# ESP32S31_RADIO register map
Vendor: Espressif; Series: ESP32-S31; File version: 3.52
Registers are 32-bit, read-write, no defined reset value unless marked. A register's access mark holds for its fields unless they carry their own. Offsets are from the block's base; [hi:lo] are bit positions.

## WIFI_MAC_INTERNAL_TX_BLOCK_ACK — Complete dbg_read_internal_txba reads one internal WDEVTXBA result: a 64-bit bitmap, two transmitter-address words and a combined fragment/starting-sequence/TID word.
Base 0x2010429C
0x00 BITMAP_HIGH ro
  [31:0] BITMAP — High 32 bits of the internal transmit BlockAck acknowledgement bitmap.
0x04 BITMAP_LOW ro
  [31:0] BITMAP — Low 32 bits of the internal transmit BlockAck acknowledgement bitmap.
0x08 TRANSMITTER_ADDRESS_WORD_0 ro — First WDEVTXBA TA word printed by the complete blob decoder. Byte ordering is retained as a raw word until a matching live frame qualifies it.
0x0C TRANSMITTER_ADDRESS_WORD_1 ro — Second WDEVTXBA TA word printed by the complete blob decoder. Byte ordering is retained as a raw word until a matching live frame qualifies it.
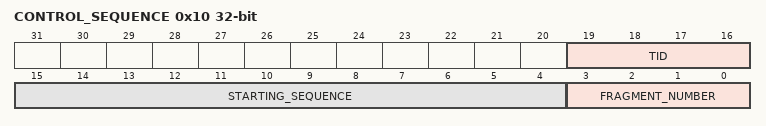
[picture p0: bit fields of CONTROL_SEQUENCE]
0x10 CONTROL_SEQUENCE ro
  [19:16] TID, [15:4] STARTING_SEQUENCE, [3:0] FRAGMENT_NUMBER

## WIFI_MAC_HE_COLOR_COLLISION — Complete dbg_read_color_collision reads the 64-bit observed BSS-color bitmap. Its adjacent control word is the canonical WIFI_MAC_HE_INIT_PREFIX.RX_FIELD_CONTROL register. Open HE HIL observed color bit 25, threshold one and timeout 60 seconds.
Base 0x20104040
0x00 BSS_COLOR_BITMAP_LOW ro — RX_HE_BSS_COLOR_MAPLO.
  [31:0] VALUE
0x04 BSS_COLOR_BITMAP_HIGH ro — RX_HE_BSS_COLOR_MAPHI.
  [31:0] VALUE

## WIFI_MAC_RX_POWER_SAVE — WDEV_RX_POWER_SAVE_CONF decoded by complete dbg_read_rx_misc. Complete hal_he_set_power_save sets the interface-zero intra-PPDU and BSS-color-check bits as the tail of hal_he_bssid_init; open associated-STA HIL read both bits set.
Base 0x201040A0
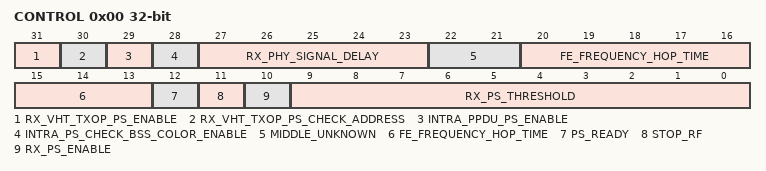
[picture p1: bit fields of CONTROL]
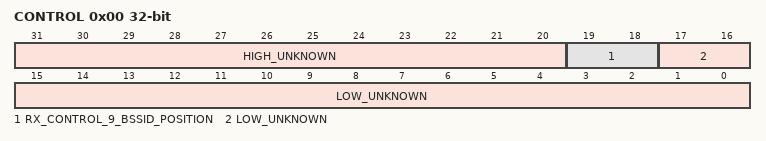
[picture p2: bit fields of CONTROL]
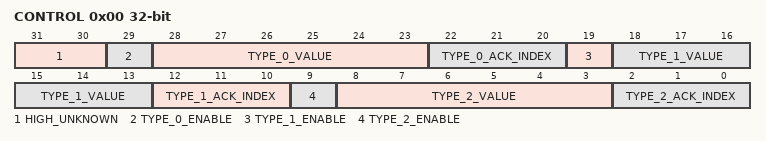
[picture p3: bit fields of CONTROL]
0x00 CONTROL
  [31] RX_VHT_TXOP_PS_ENABLE
  [30] RX_VHT_TXOP_PS_CHECK_ADDRESS
  [29] INTRA_PPDU_PS_ENABLE — Complete hal_he_set_power_save sets bit 29 for interface zero immediately before bit 28; dbg_read_rx_misc names it INTRA_PPDU_PS.
  [28] INTRA_PS_CHECK_BSS_COLOR_ENABLE — Complete hal_he_set_power_save sets bit 28 for interface zero as the final fresh-read RMW of hal_he_bssid_init; dbg_read_rx_misc names it INTRA_PS_CHECK_BSS_COLOR.
  [27:23] RX_PHY_SIGNAL_DELAY
  [22:21] MIDDLE_UNKNOWN
  [20:13] FE_FREQUENCY_HOP_TIME
  [12] PS_READY
  [11] STOP_RF
  [10] RX_PS_ENABLE
  [9:0] RX_PS_THRESHOLD

## WIFI_MAC_RX_BSSID_LIST — Canonical WDEVRXCTR_BSSIDLIST word. Complete dbg_read_rx_misc names bits 19:18 RXCTL9_BSSID_POS; the HE init prefix independently writes encoding two to that same field.
Base 0x20104110
0x00 CONTROL
  [31:20] HIGH_UNKNOWN
  [19:18] RX_CONTROL_9_BSSID_POSITION — Debug-decoded BSSID position field; complete hal_he_init writes encoding two.
  [17:0] LOW_UNKNOWN

## WIFI_MAC_RX_CUSTOM_TYPE — WDEVTXRX_TAB three custom frame-type match and ACK-index profiles decoded by complete dbg_read_rx_misc.
Base 0x20104CA4
0x00 CONTROL
  [31:30] HIGH_UNKNOWN, [29] TYPE_0_ENABLE, [28:23] TYPE_0_VALUE, [22:20] TYPE_0_ACK_INDEX, [19] TYPE_1_ENABLE, [18:13] TYPE_1_VALUE, [12:10] TYPE_1_ACK_INDEX, [9] TYPE_2_ENABLE, [8:3] TYPE_2_VALUE, [2:0] TYPE_2_ACK_INDEX

## WIFI_MAC_RX_STATISTICS — Sparse RX hardware statistics decoded by complete dbg_read_rx_count. Ten-bit and sixteen-bit masks, the signed CFO transform and every register address below follow the complete instruction body and its pinned format string. Open HE HIL observed coherent MPDU/end/data, CFO, FCS, power-drop, HT-SIG, HE-SIG-A and interrupt counts while all buffer/FIFO/TKIP counters remained zero.
Base 0x2010430C
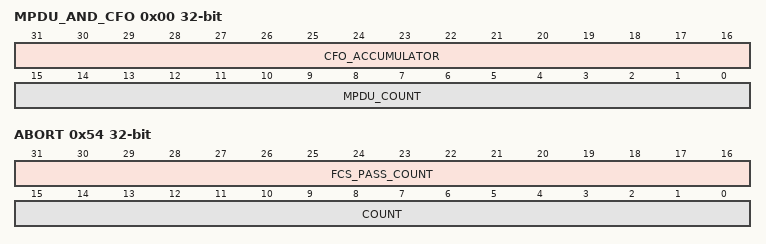
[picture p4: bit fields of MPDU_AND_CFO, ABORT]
0x00 MPDU_AND_CFO ro — WDEVRX_MPDU in bits 15:0. The blob sign-extends bits 31:16 and multiplies by 40 to print WDEVRX_CFO.
  [31:16] CFO_ACCUMULATOR, [15:0] MPDU_COUNT
0x04 BRX_ERROR_AGC ro
  [9:0] COUNT
0x08 BRX_ERROR ro
  [9:0] COUNT
0x0C NRX_ERROR ro
  [9:0] COUNT
0x10 NRX_ERROR_ABORT ro
  [9:0] COUNT
0x14 NRX_ERROR_AGC_EXIT ro
  [9:0] COUNT
0x18 NRX_ERROR_BASEBAND_OFF ro
  [9:0] COUNT
0x1C NRX_ERROR_FDM_WATCHDOG ro
  [9:0] COUNT
0x20 NRX_ERROR_POWER_DROP ro
  [9:0] COUNT
0x24 NRX_ERROR_RESTART ro
  [9:0] COUNT
0x28 NRX_ERROR_SERVICE ro
  [9:0] COUNT
0x2C NRX_ERROR_TX_OVER ro
  [9:0] COUNT
0x30 NRX_HE_UNSUPPORTED ro
  [9:0] COUNT
0x34 NRX_HE_SIG_A_CRC ro
  [9:0] COUNT
0x38 NRX_HE_FORMAT ro
  [9:0] COUNT
0x3C NRX_HE_SIG_B_ERROR ro
  [15:0] COUNT
0x40 NRX_HT_SIG_ERROR ro
  [9:0] COUNT
0x44 NRX_UNSUPPORTED ro
  [9:0] COUNT
0x50 SIGNAL_FIELD ro — WDEVRX_SF.
  [15:0] COUNT
0x54 ABORT ro
  [31:16] FCS_PASS_COUNT, [15:0] COUNT
0x58 FCS_ERROR ro
  [15:0] COUNT
0x5C FIFO_OVERFLOW ro
  [15:0] COUNT
0x60 BUFFER_FULL ro
  [15:0] COUNT
0x64 OTHER_UNICAST ro
  [15:0] COUNT
0x68 TKIP_ERROR ro
  [15:0] COUNT
0x6C SAME_BM_ERROR ro
  [15:0] COUNT
0x70 ACK_INTERRUPT ro
  [15:0] COUNT
0x74 RTS_INTERRUPT ro
  [15:0] COUNT
0x78 CTS_INTERRUPT ro — Complete dbg_lmac_hw_statis_dump prints the full word at 0x20104384 as cts_int. Its internal field width is not inferred.
  [31:0] VALUE
0x7C DATA_SUCCESS ro
  [15:0] COUNT
0x80 END ro
  [15:0] COUNT
0x84 BT_BLOCK_ERROR ro
  [15:0] COUNT
0x88 FREQUENCY_HOP_ERROR ro
  [15:0] COUNT
0x8C LAST_UNMATCHED_ERROR ro
  [15:0] COUNT
0x90 TRIGGER ro — Complete dbg_lmac_hw_statis_dump prints the full word at 0x2010439c as trigger. This is a separate hardware-statistics observation from the decoded HE Trigger RX counter at 0x20104dbc.
  [31:0] VALUE
